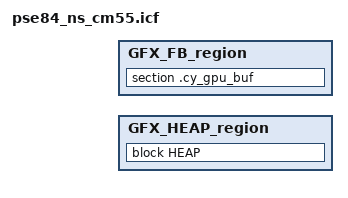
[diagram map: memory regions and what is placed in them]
/***************************************************************************//**
* \file pse84_ns_cm55.icf
* \version 1.0.0
*
* Linker file for the IAR compiler.
*
* The main purpose of this file is to describe how the sections in the
* input files should be mapped into the output file, and to control the memory
* layout of the output file.
*
*
* \note The linker files included with the PDL template projects must be generic
* and handle all common use cases. Your project may not use every section
* defined in the linker files. In that case you may see warnings during the
* build process. In your project, you can simply comment out or remove the
* relevant code in the linker file.
*
********************************************************************************
* \copyright
* Copyright (c) (2020-2025), Cypress Semiconductor Corporation (an Infineon company) or
* an affiliate of Cypress Semiconductor Corporation.
* SPDX-License-Identifier: Apache-2.0
*
* Licensed under the Apache License, Version 2.0 (the "License");
* you may not use this file except in compliance with the License.
* You may obtain a copy of the License at
*
*     http://www.apache.org/licenses/LICENSE-2.0
*
* Unless required by applicable law or agreed to in writing, software
* distributed under the License is distributed on an "AS IS" BASIS,
* WITHOUT WARRANTIES OR CONDITIONS OF ANY KIND, either express or implied.
* See the License for the specific language governing permissions and
* limitations under the License.
*******************************************************************************/

/* Include the device memory definitions generated by the Device Configurator */
include  "../../config/GeneratedSource/cymem_ilinkarm_CM55_0.icf";

/* Define the stack size for the application
  To set stack size in application add makefile ldflags: --config_def APP_MSP_STACK_SIZE=<CUSTOM_VALUE> */
if (!isdefinedsymbol(APP_MSP_STACK_SIZE))
{
  /* default stack size */
  define symbol APP_MSP_STACK_SIZE = 0x00001000;
}
define symbol __ICFEDIT_size_cstack__ = APP_MSP_STACK_SIZE;

/* Defines the minimum heap size. The actual heap size will be expanded to the end of the stack region */
if (!isdefinedsymbol(HEAP_SIZE))
{
  /* default heap size */
  define symbol HEAP_SIZE = 0x00001000;
}
define symbol __ICFEDIT_size_heap__ = HEAP_SIZE;

/* Device definitions */
define symbol VECTORS_ALIGNMENT = 0x400;
define symbol __ICFEDIT_intvec_start__ = CYMEM_CM55_0_m55_nvm_sel_START;

define memory mem with size = 4G;

/* The size of the MCU boot header area at the start of main code region */
define symbol MCUBOOT_HEADER_SIZE = 0x400;

/* Include the memory regions generated by the Device Configurator.
  This file contains the memory region definitions for the device,
  which are used to define the memory layout in this linker script. */

include  "../../config/GeneratedSource/cymem_ilinkarm_regions_CM55_0.icf";

/* Block definitions */

/* Define a block for performance-sensitive or critical functions that need to be executed in SRAM */
define block RAM_APP with alignment = 4
{
  section .cy_itcm,
  section .cy_sram_code,
  section .cy_ramfunc,
  readwrite section *.cy_os_common,
  readwrite code object ABImemclr*.*,
  readwrite code object ABImemcpy*.*,
  readwrite code object ABImemset*.*,
  readwrite code object cy_smif.*,
  readwrite code object cy_smif_sfdp.*,
  readwrite code object cy_smif_memnum.*,
  readwrite code object cy_smif_memslot.*,
  readwrite code object cy_smif_hb_flash.*,
  readwrite code object cy_syslib.*,
  readwrite code object cy_syslib_ext.*,
  readwrite code object dlmalloc.*,
  readwrite code object memcmp.*,
  readwrite code object mtb_hal_memoryspi.*,
  readwrite code object mtb_serial_memory.*,
  readwrite code object *freertos/Source*.*,
  readwrite code object *cy_clib_support*.*,
  readwrite code object *cy_mutex_pool*.*,
  readwrite code object *cy_time*.*,
  readwrite code object *cyabs*.*,
  readwrite code object *cy_worker_thread.*,
  readwrite code object *cmsis*.*,
  /* LVGL hot-path code in ITCM (core rendering + draw backends + helium blend) */
  readwrite code object */lvgl/src/core/*.*,
  readwrite code object */lvgl/src/draw/*.*,
  readwrite code object */lvgl/src/display/*.*,
  readwrite code object */lvgl/src/misc/*.*,
  readwrite code object */lvgl/src/tick/*.*,
  readwrite code object */lvgl/src/indev/*.*,
  readwrite code object */lvgl/src/layouts/*.*,
  readwrite code object */lvgl/src/osal/*.*
};

/* Define a block for less performance-sensitive LVGL code to be executed in SOC memory */
define block SOCMEM_LVGL with alignment = 4
{
  /* Demo code moved from ITCM to free space for helium blend acceleration */
  readwrite code object */lvgl/demos/music/*.*,
  readwrite code object */lvgl/demos/widgets/*.*,
  /* Less perf-critical LVGL code: fonts, widgets, stdlib, themes, others, lv_init, etc. */
  readwrite code object */lvgl/src/*.*
};

/* Define the stack and heap blocks */
define block CSTACK with alignment = 8, size = __ICFEDIT_size_cstack__ { };
define block HEAP with expanding size, alignment = 8, minimum size = __ICFEDIT_size_heap__ { };

/* Define the RAM data and bss blocks */
define block RAM_DATA { readwrite section .data };
define block RAM_BSS { readwrite section .bss };
define block RAM_OTHER { readwrite section * };
define block RAM_NOINIT { readwrite section .noinit };
define block RAM with fixed order { block RAM_DATA, block RAM_OTHER, block RAM_NOINIT, block RAM_BSS };

/* Define the RAM vector block */
define block RAM_VECTOR with alignment = VECTORS_ALIGNMENT { section .intvec_ram };

/* Initialization */
do not initialize { section .noinit, section .intvec_ram, section .cy_sharedmem };
initialize by copy
{
  readwrite,
  section .cy_itcm,
  section .cy_sram_code,
  section .cy_ramfunc,
  section .cy_socmem_data,
  section .cy_socmem_code,
  readonly section *.cy_os_common,
  readonly object ABImemclr*.*,
  readonly object ABImemcpy*.*,
  readonly object ABImemset*.*,
  readonly object cy_smif.*,
  readonly object cy_smif_sfdp.*,
  readonly object cy_smif_memnum.*,
  readonly object cy_smif_memslot.*,
  readonly object cy_smif_hb_flash.*,
  readonly object cy_syslib.*,
  readonly object cy_syslib_ext.*,
  readonly object dlmalloc.*,
  readonly object memcmp.*,
  readonly object mtb_hal_memoryspi.*,
  readonly object mtb_serial_memory.*,
  readonly object *freertos/Source*.*,
  readonly object *cy_clib_support*.*,
  readonly object *cy_mutex_pool*.*,
  readonly object *cy_time*.*,
  readonly object *cyabs*.*,
  readonly object *cy_worker_thread.*,
  readonly object *cmsis*.*,
  readonly object */lvgl/src/core/*.*,
  readonly object */lvgl/src/draw/*.*,
  readonly object */lvgl/src/display/*.*,
  readonly object */lvgl/src/misc/*.*,
  readonly object */lvgl/src/tick/*.*,
  readonly object */lvgl/src/indev/*.*,
  readonly object */lvgl/src/layouts/*.*,
  readonly object */lvgl/src/osal/*.*,
  readonly object */lvgl/demos/music/*.*,
  readonly object */lvgl/demos/widgets/*.*,
  readonly object */lvgl/src/*.*
};

/* Placement */
/* Serial Memory Interface block #0 memory #1, 16 MB */
/* A reserved region for MCUBoot header */
reserve region "MCUBOOT_HEADER" = [from start(m55_nvm_sel) size MCUBOOT_HEADER_SIZE];
/* Reserve a trail space for the signature for the bootloader - do not place any code here */
reserve region "M55_TRAILER" = [from (start(m55_trailer_sel)) size CYMEM_CM55_0_m55_trailer_SIZE];
place in m55_nvm_sel { first section .intvec, readonly };

/* ITCM, 256 KB */
/* A piece intended for code placement */
/* Reserving the first 16 bytes to avoid debug symbols (that have default address 0x0) to be confused with actual code */
reserve region "ZERO_ADDRESS_MEM" = [from start(m55_code_INTERNAL) size 16];
place in m55_code_INTERNAL { section .ram_vectors, block RAM_APP };

/* System SRAM (SoCMEM), 5 MB */
/* A piece intended for less performance-sensitive or critical functions that might be executed in SOC memory */
place in m55_code_secondary { section .cy_socmem_code, block SOCMEM_LVGL };
/* A piece intended for shared RAM memory where only the Cortex-M55 can allocate data but all cores can access */
place in m55_allocatable_shared { section .cy_sharedmem };

/* DTCM, 256 KB */
/* A piece intended for data placement */
place at start of m55_data_INTERNAL { block RAM_VECTOR };
place in          m55_data_INTERNAL { block RAM, section .cy_dtcm };
place at end   of m55_data_INTERNAL { block CSTACK };

/* System SRAM (SoCMEM), 5 MB */
/* A piece intended for data placement */
place in        m55_data_secondary { section .cy_socmem_data };

/* ---- Unified gfx_mem layout (common to all demos and displays) ----
 * The CM55 heap is a FIXED 384 KB window at the gfx_mem origin; the GPU frame
 * buffers follow it. The CM55 MPU marks the heap window Normal Write-Back
 * cacheable (design.modus region 2) to keep the benchmark fast, while the
 * frame-buffer remainder stays Non-Cacheable. The measured peak heap is
 * ~116 KB for both demos, so 384 KB serves every demo/display combination. */
define region GFX_HEAP_region = [from CYMEM_CM55_0_gfx_mem_START size 0x60000];
define region GFX_FB_region   = [from (CYMEM_CM55_0_gfx_mem_START + 0x60000) size (CYMEM_CM55_0_gfx_mem_SIZE - 0x60000)];
place in GFX_HEAP_region { block HEAP };

/* A piece intended for GPU frame buffers (placed after the heap window) */
place in GFX_FB_region { section .cy_gpu_buf };

keep { section .intvec };
